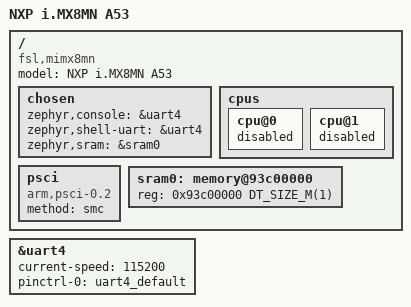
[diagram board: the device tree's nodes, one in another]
/*
 * Copyright 2022 NXP
 *
 * SPDX-License-Identifier: Apache-2.0
 */

/dts-v1/;

#include <nxp/nxp_mimx8mn_a53.dtsi>
#include "imx8mn_evk-pinctrl.dtsi"

/ {
	model = "NXP i.MX8MN A53";
	compatible = "fsl,mimx8mn";

	chosen {
		zephyr,console = &uart4;
		zephyr,shell-uart = &uart4;
		zephyr,sram = &sram0;
	};

	cpus {
		cpu@0 {
			status = "disabled";
		};
		cpu@1 {
			status = "disabled";
		};
	};

	psci {
		compatible = "arm,psci-0.2";
		method = "smc";
	};

	sram0: memory@93c00000 {
		reg = <0x93c00000 DT_SIZE_M(1)>;
	};
};

&uart4 {
	current-speed = <115200>;
	pinctrl-0 = <&uart4_default>;
	pinctrl-names = "default";
	status = "okay";
};
